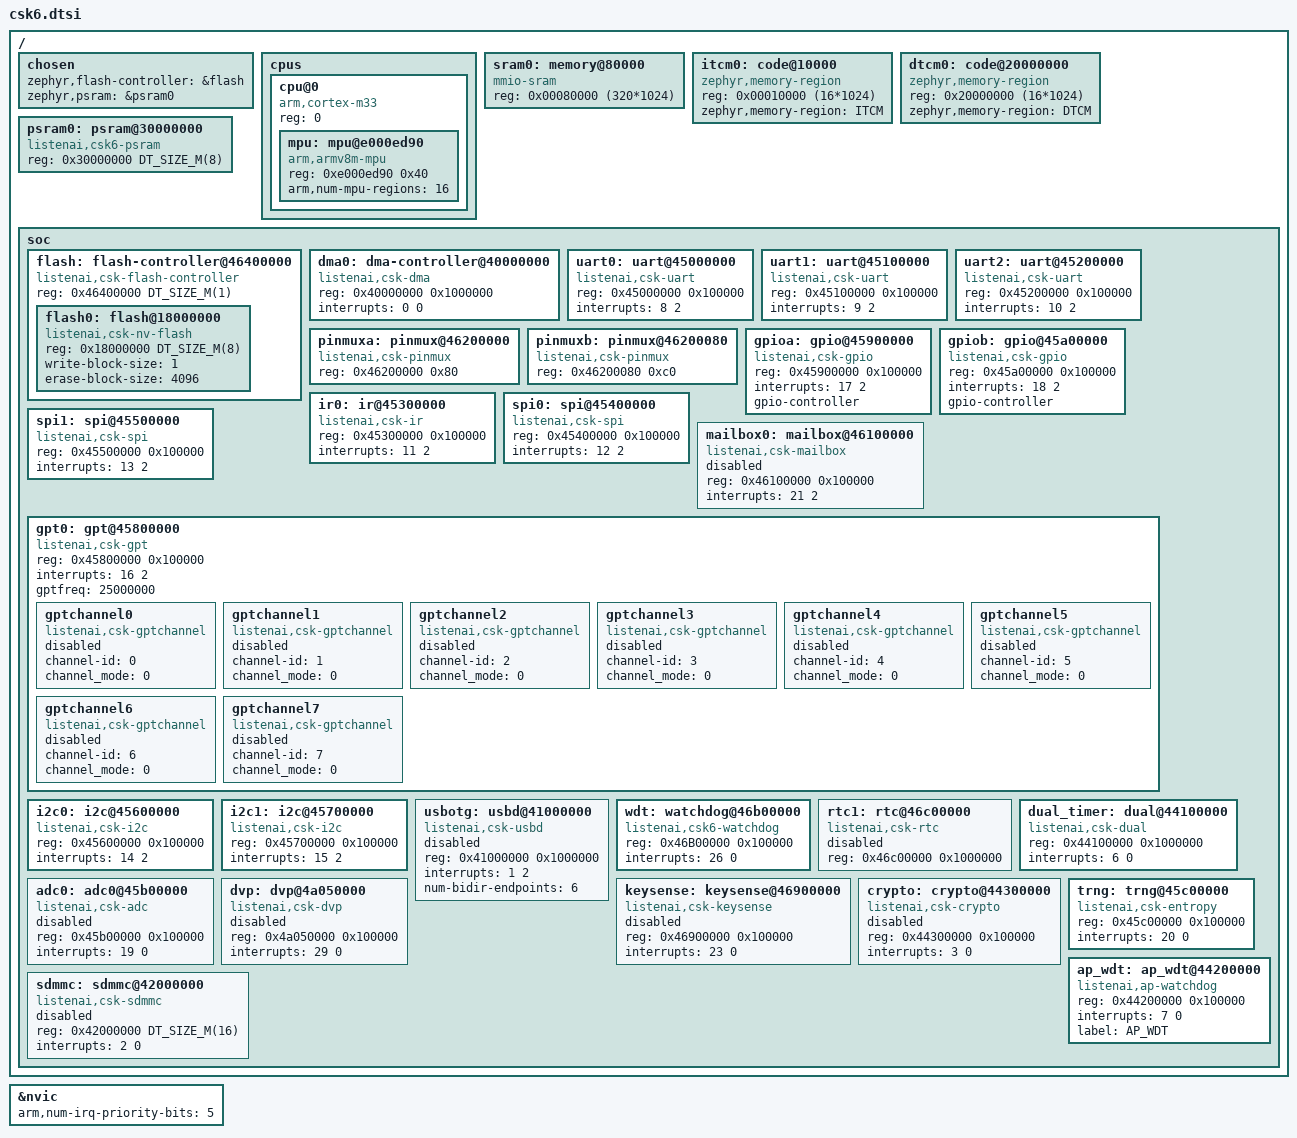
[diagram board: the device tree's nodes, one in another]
/* SPDX-License-Identifier: Apache-2.0 */

#include <mem.h>
#include <arm/armv8-m.dtsi>


/ {
	chosen {
		zephyr,flash-controller = &flash;
		zephyr,psram = &psram0;
	};
	cpus {
		#address-cells = <1>;
		#size-cells = <0>;

		cpu@0 {
			device_type = "cpu";
			compatible = "arm,cortex-m33";
			reg = <0>;
			#address-cells = <1>;
			#size-cells = <1>;

			mpu: mpu@e000ed90 {
				compatible = "arm,armv8m-mpu";
				reg = <0xe000ed90 0x40>;
				arm,num-mpu-regions = <16>;
			};

		};
	};

	sram0: memory@80000 {
		compatible = "mmio-sram";
		reg = <0x00080000 (320*1024)>;
	};

	itcm0: code@10000 {
		compatible = "zephyr,memory-region";
		reg = <0x00010000 (16*1024)>;
		zephyr,memory-region = "ITCM";
	};

	dtcm0: code@20000000 {
		compatible = "zephyr,memory-region";
		reg = <0x20000000 (16*1024)>;
		zephyr,memory-region = "DTCM";
	};

	psram0: psram@30000000 {
		compatible = "listenai,csk6-psram";
		reg = <0x30000000 DT_SIZE_M(8)>;
	};

	soc {

		flash: flash-controller@46400000 {
			compatible = "listenai,csk-flash-controller";
			reg = <0x46400000 DT_SIZE_M(1)>;
			#address-cells = <1>;
			#size-cells = <1>;


			flash0: flash@18000000 {
				compatible = "listenai,csk-nv-flash","soc-nv-flash";
				reg = <0x18000000 DT_SIZE_M(8)>;
				write-block-size = <1>;
				erase-block-size = <4096>;
			};

		};

		dma0: dma-controller@40000000 {
			compatible = "listenai,csk-dma";
			reg = <0x40000000 0x1000000>;
			interrupts = <0 0>;
			#dma-cells = <1>;
		};

		uart0: uart@45000000 {
			compatible = "listenai,csk-uart";
			reg = <0x45000000 0x100000>;
			interrupts = <8 2>;
		};

		uart1: uart@45100000 {
			compatible = "listenai,csk-uart";
			reg = <0x45100000 0x100000>;
			interrupts = <9 2>;
		};

		uart2: uart@45200000 {
			compatible = "listenai,csk-uart";
			reg = <0x45200000 0x100000>;
			interrupts = <10 2>;
		};

		pinmuxa: pinmux@46200000 {
			compatible = "listenai,csk-pinmux";
			reg = <0x46200000 0x80>;
			#pinmux-cells = <2>;
			#pinctrl-cells = <2>;
			status = "okay";
		};

		pinmuxb: pinmux@46200080 {
			compatible = "listenai,csk-pinmux";
			reg = <0x46200080 0xc0>;
			#pinmux-cells = <2>;
			#pinctrl-cells = <2>;
			status = "okay";
		};

		gpioa: gpio@45900000 {
			compatible = "listenai,csk-gpio";
			reg = <0x45900000 0x100000>;
			interrupts = <17 2>;
			gpio-controller;
			#gpio-cells = <2>;
		};

		gpiob: gpio@45a00000 {
			compatible = "listenai,csk-gpio";
			reg = <0x45a00000 0x100000>;
			interrupts = <18 2>;
			gpio-controller;
			#gpio-cells = <2>;
		};

		ir0: ir@45300000 {
			compatible = "listenai,csk-ir";
			reg = <0x45300000 0x100000>;
			interrupts = <11 2>;
		};

		spi0: spi@45400000 {
			compatible = "listenai,csk-spi";
			reg = <0x45400000 0x100000>;
			interrupts = <12 2>;
			#address-cells = <1>;
			#size-cells = <0>;
		};

		spi1: spi@45500000 {
			compatible = "listenai,csk-spi";
			reg = <0x45500000 0x100000>;
			interrupts = <13 2>;
			#address-cells = <1>;
			#size-cells = <0>;
		};

		mailbox0: mailbox@46100000 {
			compatible = "listenai,csk-mailbox";
			reg = <0x46100000 0x100000>;
			interrupts = <21 2>;
			status = "disabled";
		};

		gpt0: gpt@45800000 {
			compatible = "listenai,csk-gpt";
			reg = <0x45800000 0x100000>;
			interrupts = <16 2>;
			interrupt-names = "csk_gpt_isr";
			gptfreq = <25000000>;

			gptchannel0:gptchannel0 {
				compatible = "listenai,csk-gptchannel";
				channel-id = <0>;
				channel_mode = <0>;  /* 0: timer; 1:pwm */

				status = "disabled";
				#pwm-cells = <3>;
			};

			gptchannel1:gptchannel1 {
				compatible = "listenai,csk-gptchannel";
				channel-id = <1>;
				channel_mode = <0>;  /* 0: timer; 1:pwm */

				status = "disabled";
				#pwm-cells = <3>;
			};
			
			gptchannel2:gptchannel2 {
				compatible = "listenai,csk-gptchannel";
				channel-id = <2>;
				channel_mode = <0>;  /* 0: timer; 1:pwm */

				status = "disabled";
				#pwm-cells = <3>;
			};
			
			gptchannel3:gptchannel3 {
				compatible = "listenai,csk-gptchannel";
				channel-id = <3>;
				channel_mode = <0>;  /* 0: timer; 1:pwm */

				status = "disabled";
				#pwm-cells = <3>;
			};

			gptchannel4:gptchannel4 {
				compatible = "listenai,csk-gptchannel";
				channel-id = <4>;
				channel_mode = <0>;  /* 0: timer; 1:pwm */

				status = "disabled";
				#pwm-cells = <3>;
			};
			
			gptchannel5:gptchannel5 {
				compatible = "listenai,csk-gptchannel";
				channel-id = <5>;
				channel_mode = <0>;  /* 0: timer; 1:pwm */

				status = "disabled";
				#pwm-cells = <3>;
			};

			gptchannel6:gptchannel6 {
				compatible = "listenai,csk-gptchannel";
				channel-id = <6>;
				channel_mode = <0>;  /* 0: timer; 1:pwm */

				status = "disabled";
				#pwm-cells = <3>;
			};
			
			gptchannel7:gptchannel7 {
				compatible = "listenai,csk-gptchannel";
				channel-id = <7>;
				channel_mode = <0>;  /* 0: timer; 1:pwm */

				status = "disabled";
				#pwm-cells = <3>;
			};

		};

		i2c0: i2c@45600000 {
			compatible = "listenai,csk-i2c";
			reg = <0x45600000 0x100000>;
			interrupts = <14 2>;
			#address-cells = <1>;
			#size-cells = <0>;
		};

		i2c1: i2c@45700000 {
			compatible = "listenai,csk-i2c";
			reg = <0x45700000 0x100000>;
			interrupts = <15 2>;
			#address-cells = <1>;
			#size-cells = <0>;
		};

		usbotg: usbd@41000000 {
			compatible = "listenai,csk-usbd";
			reg = <0x41000000 0x1000000>;
			interrupts = <1 2>;
			interrupt-names = "usb_otg";
			num-bidir-endpoints = <6>;
			status = "disabled";
		};

		wdt: watchdog@46b00000 {
			compatible = "listenai,csk6-watchdog";
			reg = <0x46B00000 0x100000>;
			interrupts = <26 0>;
			status = "okay";
		};

		rtc1: rtc@46c00000 {
			compatible = "listenai,csk-rtc";
			reg = <0x46c00000 0x1000000>;
			status = "disabled";
		};
		dual_timer: dual@44100000 {
			compatible = "listenai,csk-dual";
			reg = <0x44100000 0x1000000>;
			interrupts = <6 0>;
		};
		adc0: adc0@45b00000 {
			compatible = "listenai,csk-adc";
			reg = <0x45b00000 0x100000>;
			interrupts = <19 0>;
			status = "disabled";
			#io-channel-cells = <1>;
		};

		keysense: keysense@46900000{
			compatible = "listenai,csk-keysense";
			reg = <0x46900000 0x100000>;
			interrupts = <23 0>;
			status = "disabled";
		};

		dvp: dvp@4a050000{
			compatible = "listenai,csk-dvp";
			reg = <0x4a050000 0x100000>;
			interrupts = <29 0>;
			status = "disabled";
		};
		
		crypto: crypto@44300000{
			compatible = "listenai,csk-crypto";
			reg = <0x44300000 0x100000>;
			interrupts = <3 0>;
			status = "disabled";
		};

		trng: trng@45c00000{
			compatible = "listenai,csk-entropy";
			reg = <0x45c00000 0x100000>;
			interrupts = <20 0>;
			status = "okay";
		};

		sdmmc:sdmmc@42000000{
			compatible = "listenai,csk-sdmmc";
			reg = <0x42000000 DT_SIZE_M(16)>;
			interrupts = <2 0>;
			status = "disabled";
		};

		ap_wdt: ap_wdt@44200000 {
			compatible = "listenai,ap-watchdog";
			reg = <0x44200000 0x100000>;
			interrupts = <7 0>;
			label = "AP_WDT";
			status = "okay";
		};

	};
};

&nvic {
	arm,num-irq-priority-bits = <5>;
};
